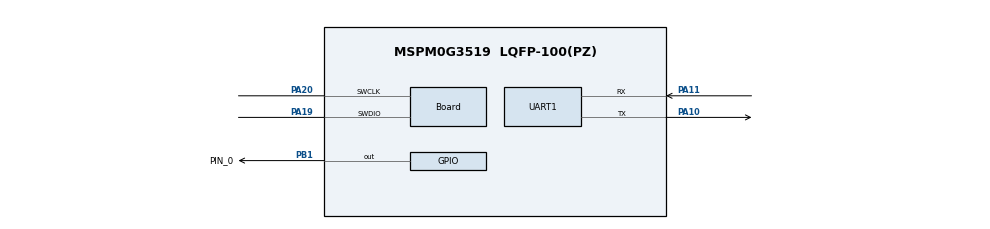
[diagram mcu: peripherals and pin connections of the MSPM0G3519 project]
/**
 * These arguments were used when this file was generated. They will be automatically applied on subsequent loads
 * via the GUI or CLI. Run CLI with '--help' for additional information on how to override these arguments.
 * @cliArgs --device "MSPM0G351X" --part "Default" --package "LQFP-100(PZ)" --product "mspm0_sdk@2.10.00.04"
 * @v2CliArgs --device "MSPM0G3519" --package "LQFP-100(PZ)" --product "mspm0_sdk@2.10.00.04"
 * @versions {"tool":"1.26.2+4477"}
 */

/**
 * Import the modules used in this configuration.
 */
const ADC12         = scripting.addModule("/ti/driverlib/ADC12", {}, false);
const ADC121        = ADC12.addInstance();
const DMA           = scripting.addModule("/ti/driverlib/DMA");
const GPIO          = scripting.addModule("/ti/driverlib/GPIO", {}, false);
const GPIO1         = GPIO.addInstance();
const SYSTICK       = scripting.addModule("/ti/driverlib/SYSTICK");
const TIMER         = scripting.addModule("/ti/driverlib/TIMER", {}, false);
const TIMER1        = TIMER.addInstance();
const UART          = scripting.addModule("/ti/driverlib/UART", {}, false);
const UART1         = UART.addInstance();
const ProjectConfig = scripting.addModule("/ti/project_config/ProjectConfig");

/**
 * Write custom configuration values to the imported modules.
 */
const divider7       = system.clockTree["PLL_PDIV"];
divider7.divideValue = 2;

const divider9       = system.clockTree["UDIV"];
divider9.divideValue = 2;

const multiplier2         = system.clockTree["PLL_QDIV"];
multiplier2.multiplyValue = 5;

const mux4       = system.clockTree["EXHFMUX"];
mux4.inputSelect = "EXHFMUX_XTAL";

const mux8       = system.clockTree["HSCLKMUX"];
mux8.inputSelect = "HSCLKMUX_SYSPLL2X";

const pinFunction4       = system.clockTree["HFXT"];
pinFunction4.inputFreq   = 40;
pinFunction4.enable      = true;
pinFunction4.HFXTStartup = 10;

ADC121.$name                             = "ADC12_0";
ADC121.trigSrc                           = "DL_ADC12_TRIG_SRC_EVENT";
ADC121.powerDownMode                     = "DL_ADC12_POWER_DOWN_MODE_MANUAL";
ADC121.sampleTime0                       = "75ns";
ADC121.enabledInterrupts                 = ["DL_ADC12_INTERRUPT_DMA_DONE"];
ADC121.configureDMA                      = true;
ADC121.sampCnt                           = 1;
ADC121.enabledDMATriggers                = ["DL_ADC12_DMA_MEM0_RESULT_LOADED"];
ADC121.subChanID                         = 1;
ADC121.adcMem0trig                       = "DL_ADC12_TRIGGER_MODE_TRIGGER_NEXT";
ADC121.repeatMode                        = true;
ADC121.peripheral.$assign                = "ADC1";
ADC121.adcPin0Config.$name               = "ti_driverlib_gpio_GPIOPinGeneric2";
ADC121.DMA_CHANNEL.$name                 = "DMA_CH2";
ADC121.DMA_CHANNEL.addressMode           = "f2b";
ADC121.DMA_CHANNEL.srcLength             = "HALF_WORD";
ADC121.DMA_CHANNEL.dstLength             = "HALF_WORD";
ADC121.DMA_CHANNEL.configureTransferSize = true;
ADC121.DMA_CHANNEL.transferSize          = 2048;

const Board                       = scripting.addModule("/ti/driverlib/Board", {}, false);
Board.peripheral.$assign          = "DEBUGSS";
Board.peripheral.swclkPin.$assign = "PA20";
Board.peripheral.swdioPin.$assign = "PA19";

DMA.enableBurst      = true;
DMA.enableRoundRobin = true;

GPIO1.port                          = "PORTB";
GPIO1.$name                         = "LED";
GPIO1.portSegment                   = "Lower";
GPIO1.associatedPins[0].$name       = "PIN_0";
GPIO1.associatedPins[0].ioStructure = "SD";
GPIO1.associatedPins[0].pin.$assign = "PB1";

const SYSCTL                 = scripting.addModule("/ti/driverlib/SYSCTL", {}, false);
SYSCTL.forceDefaultClkConfig = true;
SYSCTL.clockTreeEn           = true;

SYSTICK.periodEnable    = true;
SYSTICK.period          = 80000;
SYSTICK.interruptEnable = true;
SYSTICK.systickEnable   = true;

TIMER1.$name                       = "TIMER_0";
TIMER1.timerMode                   = "PERIODIC";
TIMER1.timerClkDiv                 = 2;
TIMER1.timerPeriod                 = "31.25us";
TIMER1.event1PublisherChannel      = 1;
TIMER1.event1ControllerInterruptEn = ["ZERO_EVENT"];

UART1.enableFIFO                       = true;
UART1.rxFifoThreshold                  = "DL_UART_RX_FIFO_LEVEL_ONE_ENTRY";
UART1.enableDMARX                      = false;
UART1.enableDMATX                      = false;
UART1.enableInternalLoopback           = true;
UART1.enableExtend                     = true;
UART1.enabledInterrupts                = ["RX_TIMEOUT_ERROR"];
UART1.$name                            = "HMI";
UART1.peripheral.rxPin.$assign         = "PA11";
UART1.peripheral.txPin.$assign         = "PA10";
UART1.txPinConfig.direction            = scripting.forceWrite("OUTPUT");
UART1.txPinConfig.hideOutputInversion  = scripting.forceWrite(false);
UART1.txPinConfig.onlyInternalResistor = scripting.forceWrite(false);
UART1.txPinConfig.passedPeripheralType = scripting.forceWrite("Digital");
UART1.txPinConfig.$name                = "ti_driverlib_gpio_GPIOPinGeneric0";
UART1.rxPinConfig.hideOutputInversion  = scripting.forceWrite(false);
UART1.rxPinConfig.onlyInternalResistor = scripting.forceWrite(false);
UART1.rxPinConfig.passedPeripheralType = scripting.forceWrite("Digital");
UART1.rxPinConfig.$name                = "ti_driverlib_gpio_GPIOPinGeneric1";
UART1.rxPinConfig.enableConfig         = true;

ProjectConfig.migrationCondition = true;
ProjectConfig.genLibCMSIS        = true;

/**
 * Pinmux solution for unlocked pins/peripherals. This ensures that minor changes to the automatic solver in a future
 * version of the tool will not impact the pinmux you originally saw.  These lines can be completely deleted in order to
 * re-solve from scratch.
 */
pinFunction4.peripheral.$suggestSolution           = "SYSCTL";
pinFunction4.peripheral.hfxInPin.$suggestSolution  = "PA5";
pinFunction4.peripheral.hfxOutPin.$suggestSolution = "PA6";
ADC121.peripheral.adcPin0.$suggestSolution         = "PA15";
ADC121.DMA_CHANNEL.peripheral.$suggestSolution     = "DMA_CH0";
TIMER1.peripheral.$suggestSolution                 = "TIMA0";
UART1.peripheral.$suggestSolution                  = "UART0";
